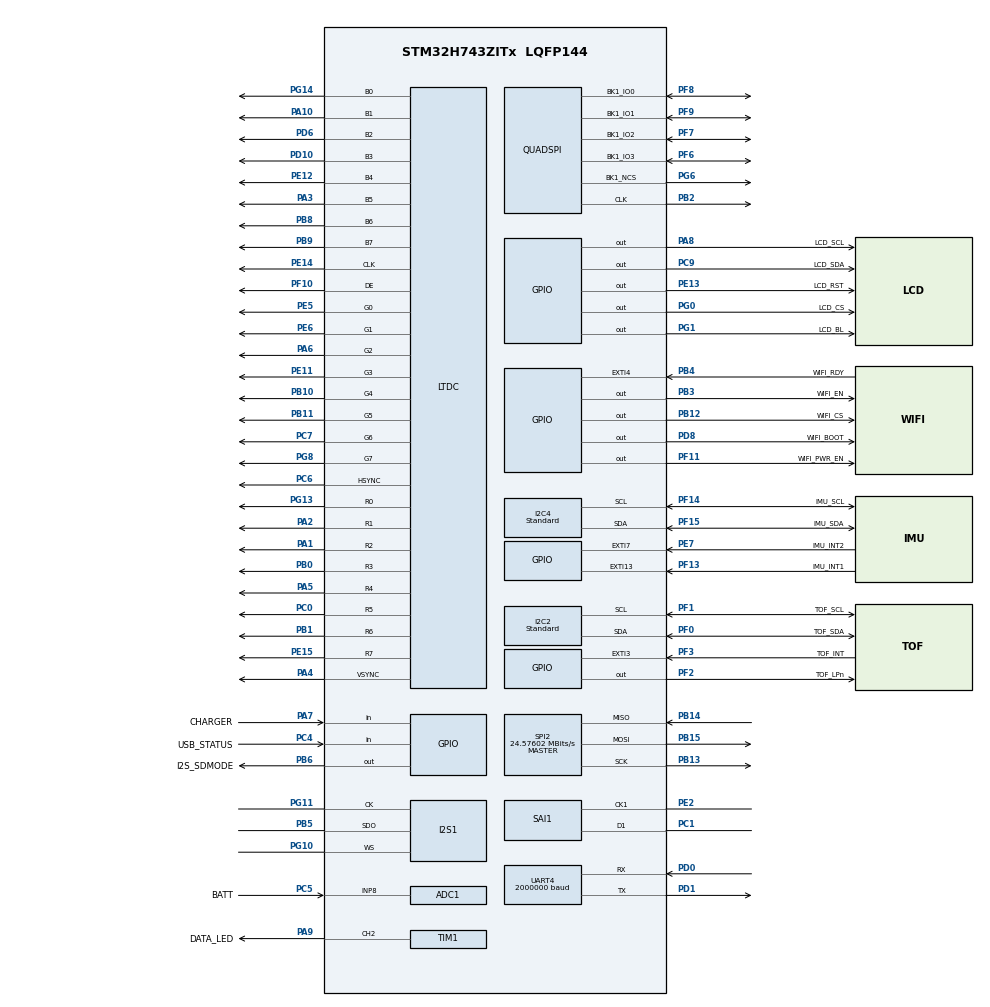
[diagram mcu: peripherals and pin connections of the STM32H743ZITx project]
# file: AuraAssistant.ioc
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ADC1.Channel-0\#ChannelRegularConversion=ADC_CHANNEL_8
ADC1.ClockPrescaler=ADC_CLOCK_ASYNC_DIV4
ADC1.EnableInjectedConversion=DISABLE
ADC1.NbrOfConversion=1
ADC1.NbrOfConversionFlag=1
ADC1.OffsetNumber-0\#ChannelRegularConversion=ADC_OFFSET_NONE
ADC1.OffsetSignedSaturation-0\#ChannelRegularConversion=DISABLE
ADC1.OversamplingMode=ENABLE
ADC1.Rank-0\#ChannelRegularConversion=1
ADC1.Ratio=16
ADC1.Resolution=ADC_RESOLUTION_16B
ADC1.RightBitShift=ADC_RIGHTBITSHIFT_4
ADC1.SamplingTime-0\#ChannelRegularConversion=ADC_SAMPLETIME_387CYCLES_5
ADC1.master=1
CORTEX_M7.AccessPermission_S-Cortex_Memory_Protection_Unit_Region1_Settings_S=MPU_REGION_PRIV_RO_URO
CORTEX_M7.AccessPermission_S-Cortex_Memory_Protection_Unit_Region2_Settings_S=MPU_REGION_FULL_ACCESS
CORTEX_M7.BaseAddress_S-Cortex_Memory_Protection_Unit_Region1_Settings_S=0x90000000
CORTEX_M7.BaseAddress_S-Cortex_Memory_Protection_Unit_Region2_Settings_S=0x24000000
CORTEX_M7.CPU_DCache=Enabled
CORTEX_M7.CPU_ICache=Enabled
CORTEX_M7.DisableExec_S-Cortex_Memory_Protection_Unit_Region1_Settings_S=MPU_INSTRUCTION_ACCESS_DISABLE
CORTEX_M7.DisableExec_S-Cortex_Memory_Protection_Unit_Region2_Settings_S=MPU_INSTRUCTION_ACCESS_DISABLE
CORTEX_M7.Enable_S-Cortex_Memory_Protection_Unit_Region1_Settings_S=MPU_REGION_ENABLE
CORTEX_M7.Enable_S-Cortex_Memory_Protection_Unit_Region2_Settings_S=MPU_REGION_ENABLE
CORTEX_M7.IsCacheable_S-Cortex_Memory_Protection_Unit_Region1_Settings_S=MPU_ACCESS_CACHEABLE
CORTEX_M7.IsCacheable_S-Cortex_Memory_Protection_Unit_Region2_Settings_S=MPU_ACCESS_NOT_CACHEABLE
CORTEX_M7.Size_S-Cortex_Memory_Protection_Unit_Region1_Settings_S=MPU_REGION_SIZE_16MB
CORTEX_M7.Size_S-Cortex_Memory_Protection_Unit_Region2_Settings_S=MPU_REGION_SIZE_512KB
CORTEX_M7.SubRegionDisable_S-Cortex_Memory_Protection_Unit_Region1_Settings_S=0x00
CORTEX_M7.SubRegionDisable_S-Cortex_Memory_Protection_Unit_Region2_Settings_S=0x00
CORTEX_M7.TypeExtField_S-Cortex_Memory_Protection_Unit_Region2_Settings_S=MPU_TEX_LEVEL1
CORTEX_M7.default_mode_Activation=1
DMA2D.ColorMode=DMA2D_OUTPUT_RGB565
Dma.Request0=SPI1_TX
Dma.Request1=SAI1_A
Dma.Request2=TIM1_CH2
Dma.Request3=SPI2_TX
Dma.Request4=SPI2_RX
Dma.SAI1_A.1.Direction=DMA_PERIPH_TO_MEMORY
Dma.SAI1_A.1.EventEnable=DISABLE
Dma.SAI1_A.1.FIFOMode=DMA_FIFOMODE_DISABLE
Dma.SAI1_A.1.Instance=DMA1_Stream1
Dma.SAI1_A.1.MemDataAlignment=DMA_MDATAALIGN_HALFWORD
Dma.SAI1_A.1.MemInc=DMA_MINC_ENABLE
Dma.SAI1_A.1.Mode=DMA_CIRCULAR
Dma.SAI1_A.1.PeriphDataAlignment=DMA_PDATAALIGN_HALFWORD
Dma.SAI1_A.1.PeriphInc=DMA_PINC_DISABLE
Dma.SAI1_A.1.Polarity=HAL_DMAMUX_REQ_GEN_RISING
Dma.SAI1_A.1.Priority=DMA_PRIORITY_HIGH
Dma.SAI1_A.1.RequestNumber=1
Dma.SAI1_A.1.SignalID=NONE
Dma.SAI1_A.1.SyncEnable=DISABLE
Dma.SAI1_A.1.SyncPolarity=HAL_DMAMUX_SYNC_NO_EVENT
Dma.SAI1_A.1.SyncRequestNumber=1
Dma.SAI1_A.1.SyncSignalID=NONE
Dma.SPI1_TX.0.Direction=DMA_MEMORY_TO_PERIPH
Dma.SPI1_TX.0.EventEnable=DISABLE
Dma.SPI1_TX.0.FIFOMode=DMA_FIFOMODE_DISABLE
Dma.SPI1_TX.0.Instance=DMA1_Stream0
Dma.SPI1_TX.0.MemDataAlignment=DMA_MDATAALIGN_HALFWORD
Dma.SPI1_TX.0.MemInc=DMA_MINC_ENABLE
Dma.SPI1_TX.0.Mode=DMA_NORMAL
Dma.SPI1_TX.0.PeriphDataAlignment=DMA_PDATAALIGN_HALFWORD
Dma.SPI1_TX.0.PeriphInc=DMA_PINC_DISABLE
Dma.SPI1_TX.0.Polarity=HAL_DMAMUX_REQ_GEN_RISING
Dma.SPI1_TX.0.Priority=DMA_PRIORITY_HIGH
Dma.SPI1_TX.0.RequestNumber=1
Dma.SPI1_TX.0.SignalID=NONE
Dma.SPI1_TX.0.SyncEnable=DISABLE
Dma.SPI1_TX.0.SyncPolarity=HAL_DMAMUX_SYNC_NO_EVENT
Dma.SPI1_TX.0.SyncRequestNumber=1
Dma.SPI1_TX.0.SyncSignalID=NONE
Dma.SPI2_RX.4.Direction=DMA_PERIPH_TO_MEMORY
Dma.SPI2_RX.4.EventEnable=DISABLE
Dma.SPI2_RX.4.FIFOMode=DMA_FIFOMODE_DISABLE
Dma.SPI2_RX.4.Instance=DMA1_Stream2
Dma.SPI2_RX.4.MemDataAlignment=DMA_MDATAALIGN_BYTE
Dma.SPI2_RX.4.MemInc=DMA_MINC_ENABLE
Dma.SPI2_RX.4.Mode=DMA_NORMAL
Dma.SPI2_RX.4.PeriphDataAlignment=DMA_PDATAALIGN_BYTE
Dma.SPI2_RX.4.PeriphInc=DMA_PINC_DISABLE
Dma.SPI2_RX.4.Polarity=HAL_DMAMUX_REQ_GEN_RISING
Dma.SPI2_RX.4.Priority=DMA_PRIORITY_HIGH
Dma.SPI2_RX.4.RequestNumber=1
Dma.SPI2_RX.4.SignalID=NONE
Dma.SPI2_RX.4.SyncEnable=DISABLE
Dma.SPI2_RX.4.SyncPolarity=HAL_DMAMUX_SYNC_NO_EVENT
Dma.SPI2_RX.4.SyncRequestNumber=1
Dma.SPI2_RX.4.SyncSignalID=NONE
Dma.SPI2_TX.3.Direction=DMA_MEMORY_TO_PERIPH
Dma.SPI2_TX.3.EventEnable=DISABLE
Dma.SPI2_TX.3.FIFOMode=DMA_FIFOMODE_DISABLE
Dma.SPI2_TX.3.Instance=DMA1_Stream3
Dma.SPI2_TX.3.MemDataAlignment=DMA_MDATAALIGN_BYTE
Dma.SPI2_TX.3.MemInc=DMA_MINC_ENABLE
Dma.SPI2_TX.3.Mode=DMA_NORMAL
Dma.SPI2_TX.3.PeriphDataAlignment=DMA_PDATAALIGN_BYTE
Dma.SPI2_TX.3.PeriphInc=DMA_PINC_DISABLE
Dma.SPI2_TX.3.Polarity=HAL_DMAMUX_REQ_GEN_RISING
Dma.SPI2_TX.3.Priority=DMA_PRIORITY_HIGH
Dma.SPI2_TX.3.RequestNumber=1
Dma.SPI2_TX.3.SignalID=NONE
Dma.SPI2_TX.3.SyncEnable=DISABLE
Dma.SPI2_TX.3.SyncPolarity=HAL_DMAMUX_SYNC_NO_EVENT
Dma.SPI2_TX.3.SyncRequestNumber=1
Dma.SPI2_TX.3.SyncSignalID=NONE
Dma.TIM1_CH2.2.Direction=DMA_MEMORY_TO_PERIPH
Dma.TIM1_CH2.2.EventEnable=DISABLE
Dma.TIM1_CH2.2.FIFOMode=DMA_FIFOMODE_DISABLE
Dma.TIM1_CH2.2.Instance=DMA1_Stream4
Dma.TIM1_CH2.2.MemDataAlignment=DMA_MDATAALIGN_HALFWORD
Dma.TIM1_CH2.2.MemInc=DMA_MINC_ENABLE
Dma.TIM1_CH2.2.Mode=DMA_NORMAL
Dma.TIM1_CH2.2.PeriphDataAlignment=DMA_PDATAALIGN_HALFWORD
Dma.TIM1_CH2.2.PeriphInc=DMA_PINC_DISABLE
Dma.TIM1_CH2.2.Polarity=HAL_DMAMUX_REQ_GEN_RISING
Dma.TIM1_CH2.2.Priority=DMA_PRIORITY_MEDIUM
Dma.TIM1_CH2.2.RequestNumber=1
Dma.TIM1_CH2.2.SignalID=NONE
Dma.TIM1_CH2.2.SyncEnable=DISABLE
Dma.TIM1_CH2.2.SyncPolarity=HAL_DMAMUX_SYNC_NO_EVENT
Dma.TIM1_CH2.2.SyncRequestNumber=1
Dma.TIM1_CH2.2.SyncSignalID=NONE
FREERTOS.BinarySemaphores01=WiFiReadySem,Dynamic,NULL,Depleted
FREERTOS.Tasks01=SystemTask,24,1024,System_Task,Default,NULL,Dynamic,NULL,NULL;TouchGFXTask,24,4096,TouchGFX_Task,As external,NULL,Dynamic,NULL,NULL;AudioInputTask,40,2048,AudioInput_Task,Default,NULL,Dynamic,NULL,NULL;WiFiTask,32,2048,WiFi_Task,Default,NULL,Dynamic,NULL,NULL;SensorTask,24,1024,Sensor_Task,Default,NULL,Dynamic,NULL,NULL;PowerTask,8,512,Power_Task,Default,NULL,Dynamic,NULL,NULL;LEDTask,16,512,LED_Task,Default,NULL,Dynamic,NULL,NULL;LoggingTask,8,1024,Logging_Task,Default,NULL,Dynamic,NULL,NULL;AudioOutputTask,40,2048,AudioOutput_Task,Default,NULL,Dynamic,NULL,NULL
FREERTOS.configCHECK_FOR_STACK_OVERFLOW=1
FREERTOS.configTOTAL_HEAP_SIZE=96000
FREERTOS.configUSE_NEWLIB_REENTRANT=1
I2C2.I2C_Speed_Mode=I2C_Standard
I2C2.Timing=0x307075B1
I2C4.I2C_Speed_Mode=I2C_Standard
I2C4.Timing=0x307075B1
I2S1.AudioFreq=I2S_AUDIOFREQ_48K
I2S1.ErrorAudioFreq=0.0 %
I2S1.Instance=SPI$Index
I2S1.RealAudioFreq=48.0 KHz
LTDC.ActiveW=480
LTDC.Alpha_L0=255
LTDC.HBP=20
LTDC.HFP=20
LTDC.ImageHeight_L0=480
LTDC.ImageWidth_L0=480
LTDC.Layers=0
LTDC.PixelFormat_L0=LTDC_PIXEL_FORMAT_RGB565
LTDC.PCPolarity=LTDC_PCPOLARITY_IIPC
LTDC.VBP=16
LTDC.VFP=16
LTDC.WindowX1_L0=480
LTDC.WindowY1_L0=480
Mcu.Family=STM32H7
Mcu.Name=STM32H743ZITx
Mcu.Package=LQFP144
NVIC.DMA1_Stream0_IRQn=true\:5\:0\:false\:false\:true\:true\:false\:true\:true
NVIC.DMA1_Stream1_IRQn=true\:5\:0\:false\:false\:true\:true\:false\:true\:true
NVIC.DMA1_Stream2_IRQn=true\:6\:0\:true\:false\:true\:true\:false\:true\:true
NVIC.DMA1_Stream3_IRQn=true\:6\:0\:true\:false\:true\:true\:false\:true\:true
NVIC.DMA1_Stream4_IRQn=true\:7\:0\:true\:false\:true\:true\:false\:true\:true
NVIC.DMA2D_IRQn=true\:6\:0\:true\:false\:true\:true\:true\:true\:true
NVIC.EXTI15_10_IRQn=true\:8\:0\:true\:false\:true\:true\:true\:true\:true
NVIC.EXTI3_IRQn=true\:7\:0\:true\:false\:true\:true\:true\:true\:true
NVIC.EXTI4_IRQn=true\:6\:0\:true\:false\:true\:true\:true\:true\:true
NVIC.EXTI9_5_IRQn=true\:8\:0\:true\:false\:true\:true\:true\:true\:true
NVIC.LTDC_IRQn=true\:5\:0\:true\:false\:true\:true\:true\:true\:true
NVIC.PriorityGroup=NVIC_PRIORITYGROUP_4
NVIC.SAI1_IRQn=true\:6\:0\:true\:false\:true\:true\:true\:true\:true
NVIC.SPI1_IRQn=true\:5\:0\:false\:false\:true\:true\:true\:true\:true
NVIC.SPI2_IRQn=true\:6\:0\:true\:false\:true\:true\:false\:true\:true
NVIC.TIM6_DAC_IRQn=true\:4\:0\:true\:false\:true\:false\:false\:true\:true
NVIC.TimeBase=TIM6_DAC_IRQn
NVIC.TimeBaseIP=TIM6
PA1.GPIO_Speed=GPIO_SPEED_FREQ_MEDIUM
PA1.Mode=RGB888
PA1.Signal=LTDC_R2
PA10.GPIO_Speed=GPIO_SPEED_FREQ_MEDIUM
PA10.Mode=RGB888
PA10.Signal=LTDC_B1
PA13\ (JTMS/SWDIO).Mode=Serial_Wire
PA13\ (JTMS/SWDIO).Signal=DEBUG_JTMS-SWDIO
PA14\ (JTCK/SWCLK).Mode=Serial_Wire
PA14\ (JTCK/SWCLK).Signal=DEBUG_JTCK-SWCLK
PA2.GPIO_Speed=GPIO_SPEED_FREQ_MEDIUM
PA2.Mode=RGB888
PA2.Signal=LTDC_R1
PA3.GPIO_Speed=GPIO_SPEED_FREQ_MEDIUM
PA3.Mode=RGB888
PA3.Signal=LTDC_B5
PA4.GPIO_Speed=GPIO_SPEED_FREQ_MEDIUM
PA4.Mode=RGB888
PA4.Signal=LTDC_VSYNC
PA5.GPIO_Speed=GPIO_SPEED_FREQ_MEDIUM
PA5.Mode=RGB888
PA5.Signal=LTDC_R4
PA6.GPIO_Speed=GPIO_SPEED_FREQ_MEDIUM
PA6.Mode=RGB888
PA6.Signal=LTDC_G2
PA7.GPIO_Label=CHARGER
PA7.Signal=GPIO_Input
PA8.GPIO_Label=LCD_SCL
PA8.Signal=GPIO_Output
PA9.GPIO_Label=DATA_LED
PA9.GPIO_Speed=GPIO_SPEED_FREQ_VERY_HIGH
PA9.Signal=S_TIM1_CH2
PB0.GPIO_Speed=GPIO_SPEED_FREQ_MEDIUM
PB0.Mode=RGB888
PB0.Signal=LTDC_R3
PB1.GPIO_Speed=GPIO_SPEED_FREQ_MEDIUM
PB1.Mode=RGB888
PB1.Signal=LTDC_R6
PB10.GPIO_Speed=GPIO_SPEED_FREQ_MEDIUM
PB10.Mode=RGB888
PB10.Signal=LTDC_G4
PB11.GPIO_Speed=GPIO_SPEED_FREQ_MEDIUM
PB11.Mode=RGB888
PB11.Signal=LTDC_G5
PB12.GPIO_Label=WIFI_CS
PB12.GPIO_Speed=GPIO_SPEED_FREQ_VERY_HIGH
PB12.Signal=GPIO_Output
PB13.GPIO_Speed=GPIO_SPEED_FREQ_VERY_HIGH
PB13.Mode=Full_Duplex_Master
PB13.Signal=SPI2_SCK
PB14.GPIO_Speed=GPIO_SPEED_FREQ_VERY_HIGH
PB14.Mode=Full_Duplex_Master
PB14.Signal=SPI2_MISO
PB15.GPIO_Speed=GPIO_SPEED_FREQ_VERY_HIGH
PB15.Mode=Full_Duplex_Master
PB15.Signal=SPI2_MOSI
PB2.GPIO_Speed=GPIO_SPEED_FREQ_VERY_HIGH
PB2.Mode=Single Bank 1
PB2.Signal=QUADSPI_CLK
PB3\ (JTDO/TRACESWO).GPIO_Label=WIFI_EN
PB3\ (JTDO/TRACESWO).PinAttribute=Free
PB3\ (JTDO/TRACESWO).Signal=GPIO_Output
PB4\ (NJTRST).GPIO_Label=WIFI_RDY
PB4\ (NJTRST).GPIO_ModeDefaultEXTI=GPIO_MODE_IT_RISING_FALLING
PB4\ (NJTRST).Signal=GPXTI4
PB5.Mode=Half_Duplex_Master_Tx
PB5.PinAttribute=Free
PB5.Signal=I2S1_SDO
PB6.GPIO_Label=I2S_SDMODE
PB6.PinAttribute=Free
PB6.PinState=GPIO_PIN_RESET
PB6.Signal=GPIO_Output
PB8.GPIO_Speed=GPIO_SPEED_FREQ_MEDIUM
PB8.Mode=RGB888
PB8.PinAttribute=Free
PB8.Signal=LTDC_B6
PB9.GPIO_Speed=GPIO_SPEED_FREQ_MEDIUM
PB9.Mode=RGB888
PB9.PinAttribute=Free
PB9.Signal=LTDC_B7
PC0.GPIO_Speed=GPIO_SPEED_FREQ_MEDIUM
PC0.Mode=RGB888
PC0.Signal=LTDC_R5
PC1.Mode=PDM_Master_Mode_CK1
PC1.Signal=SAI1_D1
PC14-OSC32_IN\ (OSC32_IN).Mode=LSE-External-Oscillator
PC14-OSC32_IN\ (OSC32_IN).Signal=RCC_OSC32_IN
PC15-OSC32_OUT\ (OSC32_OUT).Mode=LSE-External-Oscillator
PC15-OSC32_OUT\ (OSC32_OUT).Signal=RCC_OSC32_OUT
PC4.GPIO_Label=USB_STATUS
PC4.Signal=GPIO_Input
PC5.GPIO_Label=BATT
PC5.Signal=ADCx_INP8
PC6.GPIO_Speed=GPIO_SPEED_FREQ_MEDIUM
PC6.Mode=RGB888
PC6.Signal=LTDC_HSYNC
PC7.GPIO_Speed=GPIO_SPEED_FREQ_MEDIUM
PC7.Mode=RGB888
PC7.Signal=LTDC_G6
PC9.GPIO_Label=LCD_SDA
PC9.Signal=GPIO_Output
PD0.GPIO_Speed=GPIO_SPEED_FREQ_HIGH
PD0.Mode=Asynchronous
PD0.Signal=UART4_RX
PD1.GPIO_Speed=GPIO_SPEED_FREQ_HIGH
PD1.Mode=Asynchronous
PD1.Signal=UART4_TX
PD10.GPIO_Speed=GPIO_SPEED_FREQ_MEDIUM
PD10.Mode=RGB888
PD10.Signal=LTDC_B3
PD6.GPIO_Speed=GPIO_SPEED_FREQ_MEDIUM
PD6.Mode=RGB888
PD6.Signal=LTDC_B2
PD8.GPIO_Label=WIFI_BOOT
PD8.Signal=GPIO_Output
PE11.GPIO_Speed=GPIO_SPEED_FREQ_MEDIUM
PE11.Mode=RGB888
PE11.Signal=LTDC_G3
PE12.GPIO_Speed=GPIO_SPEED_FREQ_MEDIUM
PE12.Mode=RGB888
PE12.Signal=LTDC_B4
PE13.GPIO_Label=LCD_RST
PE13.Signal=GPIO_Output
PE14.GPIO_Speed=GPIO_SPEED_FREQ_MEDIUM
PE14.Mode=RGB888
PE14.Signal=LTDC_CLK
PE15.GPIO_Speed=GPIO_SPEED_FREQ_MEDIUM
PE15.Mode=RGB888
PE15.Signal=LTDC_R7
PE2.Mode=PDM_Master_Mode_CK1
PE2.Signal=SAI1_CK1
PE5.GPIO_Speed=GPIO_SPEED_FREQ_MEDIUM
PE5.Mode=RGB888
PE5.Signal=LTDC_G0
PE6.GPIO_Speed=GPIO_SPEED_FREQ_MEDIUM
PE6.Mode=RGB888
PE6.Signal=LTDC_G1
PE7.GPIO_Label=IMU_INT2
PE7.GPIO_ModeDefaultEXTI=GPIO_MODE_IT_RISING
PE7.Signal=GPXTI7
PF0.GPIO_Label=TOF_SDA
PF0.GPIO_Pu=GPIO_PULLUP
PF0.Mode=I2C
PF0.Signal=I2C2_SDA
PF1.GPIO_Label=TOF_SCL
PF1.GPIO_Pu=GPIO_PULLUP
PF1.Mode=I2C
PF1.Signal=I2C2_SCL
PF10.GPIO_Speed=GPIO_SPEED_FREQ_MEDIUM
PF10.Mode=RGB888
PF10.Signal=LTDC_DE
PF11.GPIO_Label=WIFI_PWR_EN
PF11.Signal=GPIO_Output
PF13.GPIO_Label=IMU_INT1
PF13.GPIO_ModeDefaultEXTI=GPIO_MODE_IT_RISING
PF13.Signal=GPXTI13
PF14.GPIO_Label=IMU_SCL
PF14.GPIO_Pu=GPIO_PULLUP
PF14.Mode=I2C
PF14.Signal=I2C4_SCL
PF15.GPIO_Label=IMU_SDA
PF15.GPIO_Pu=GPIO_PULLUP
PF15.Mode=I2C
PF15.Signal=I2C4_SDA
PF2.GPIO_Label=TOF_LPn
PF2.PinState=GPIO_PIN_SET
PF2.Signal=GPIO_Output
PF3.GPIO_Label=TOF_INT
PF3.GPIO_ModeDefaultEXTI=GPIO_MODE_IT_FALLING
PF3.Signal=GPXTI3
PF6.GPIO_Speed=GPIO_SPEED_FREQ_VERY_HIGH
PF6.Mode=Single Bank 1
PF6.Signal=QUADSPI_BK1_IO3
PF7.GPIO_Speed=GPIO_SPEED_FREQ_VERY_HIGH
PF7.Mode=Single Bank 1
PF7.Signal=QUADSPI_BK1_IO2
PF8.GPIO_Speed=GPIO_SPEED_FREQ_VERY_HIGH
PF8.Mode=Single Bank 1
PF8.Signal=QUADSPI_BK1_IO0
PF9.GPIO_Speed=GPIO_SPEED_FREQ_VERY_HIGH
PF9.Mode=Single Bank 1
PF9.Signal=QUADSPI_BK1_IO1
PG0.GPIO_Label=LCD_CS
PG0.PinState=GPIO_PIN_SET
PG0.Signal=GPIO_Output
PG1.GPIO_Label=LCD_BL
PG1.PinState=GPIO_PIN_RESET
PG1.Signal=GPIO_Output
PG10.Mode=Half_Duplex_Master_Tx
PG10.Signal=I2S1_WS
PG11.Mode=Half_Duplex_Master_Tx
PG11.PinAttribute=Free
PG11.Signal=I2S1_CK
PG13.GPIO_Speed=GPIO_SPEED_FREQ_MEDIUM
PG13.Mode=RGB888
PG13.PinAttribute=Free
PG13.Signal=LTDC_R0
PG14.GPIO_Speed=GPIO_SPEED_FREQ_MEDIUM
PG14.Mode=RGB888
PG14.PinAttribute=Free
PG14.Signal=LTDC_B0
PG6.GPIO_Speed=GPIO_SPEED_FREQ_VERY_HIGH
PG6.Mode=Single Bank 1
PG6.Signal=QUADSPI_BK1_NCS
PG8.GPIO_Speed=GPIO_SPEED_FREQ_MEDIUM
PG8.Mode=RGB888
PG8.Signal=LTDC_G7
PH0-OSC_IN\ (PH0).Mode=HSE-External-Oscillator
PH0-OSC_IN\ (PH0).Signal=RCC_OSC_IN
PH1-OSC_OUT\ (PH1).Mode=HSE-External-Oscillator
PH1-OSC_OUT\ (PH1).Signal=RCC_OSC_OUT
ProjectManager.HeapSize=0x200
ProjectManager.StackSize=0x400
ProjectManager.TargetToolchain=CMake
QUADSPI.ChipSelectHighTime=QSPI_CS_HIGH_TIME_7_CYCLE
QUADSPI.ClockPrescaler=1
QUADSPI.FifoThreshold=4
QUADSPI.FlashSize=23
QUADSPI.SampleShifting=QSPI_SAMPLE_SHIFTING_HALFCYCLE
RCC.ADCFreq_Value=49152038.57421875
RCC.APB1Freq_Value=120000000
RCC.APB2Freq_Value=120000000
RCC.APB3Freq_Value=120000000
RCC.APB4Freq_Value=120000000
RCC.CortexFreq_Value=480000000
RCC.D1PPRE=RCC_APB3_DIV2
RCC.D2PPRE1=RCC_APB1_DIV2
RCC.D2PPRE2=RCC_APB2_DIV2
RCC.D3PPRE=RCC_APB4_DIV2
RCC.DIVM1=5
RCC.DIVM2=5
RCC.DIVM3=2
RCC.DIVN1=192
RCC.DIVN2=98
RCC.DIVN3=32
RCC.DIVP2=10
RCC.DIVP3=1
RCC.DIVQ1=8
RCC.DIVQ2=4
RCC.DIVR3=25
RCC.EnbaleCSS=true
RCC.HCLKFreq_Value=240000000
RCC.HPRE=RCC_HCLK_DIV2
RCC.PLL2FRACN=2491
RCC.PLL3FRACN=0
RCC.PLLFRACN=0
RCC.PLLSourceVirtual=RCC_PLLSOURCE_HSE
RCC.SAI1CLockSelection=RCC_SAI1CLKSOURCE_PLL2
RCC.SPI123CLockSelection=RCC_SPI123CLKSOURCE_PLL2
RCC.SYSCLKFreq_VALUE=480000000
RCC.SYSCLKSource=RCC_SYSCLKSOURCE_PLLCLK
RCC.USBFreq_Value=120000000
SAI1.Activation=ENABLE
SAI1.AudioFrequency-PDM_Master_Mode_CK1=SAI_AUDIO_FREQUENCY_MCKDIV
SAI1.DataSize-PDM_Master_Mode_CK1=SAI_DATASIZE_16
SAI1.ErrorAudioFreq-PDM_Master_Mode_CK1=1100.0 %
SAI1.FSPolarity-PDM_Master_Mode_CK1=SAI_FS_ACTIVE_HIGH
SAI1.FrameLength-PDM_Master_Mode_CK1=16
SAI1.Instance-PDM_Master_Mode_CK1=SAI$Index_Block_A
SAI1.MClockEnable-PDM_Master_Mode_CK1=SAI_MASTERCLOCK_DISABLE
SAI1.MckOverSampling-PDM_Master_Mode_CK1=SAI_MCK_OVERSAMPLING_DISABLE
SAI1.Mckdiv-PDM_Master_Mode_CK1=12
SAI1.MicPairsNbr=1
SAI1.NoDivider-PDM_Master_Mode_CK1=SAI_MASTERDIVIDER_DISABLE
SAI1.RealAudioFreq-PDM_Master_Mode_CK1=0 Hz
SAI1.SlotActive-PDM_Master_Mode_CK1=0x0000FFFF
SAI1.SlotNumber-PDM_Master_Mode_CK1=1
SAI1.VirtualMode-PDM_Master_Mode_CK1=VM_MASTER
SAI1.VirtualProtocol-PDM_Master_Mode_CK1=VM_PDM_PROTOCOL
SAI1.VirtualSlotActive-PDM_Master_Mode_CK1=SAI_SLOTACTIVE_ALL
SH.ADCx_INP8.0=ADC1_INP8,IN8-Single-Ended
SH.S_TIM1_CH2.0=TIM1_CH2,PWM Generation2 CH2
SPI2.BaudRatePrescaler=SPI_BAUDRATEPRESCALER_2
SPI2.CalculateBaudRate=24.57602 MBits/s
SPI2.DataSize=SPI_DATASIZE_8BIT
SPI2.Direction=SPI_DIRECTION_2LINES
SPI2.Mode=SPI_MODE_MASTER
SPI2.NSSPMode=SPI_NSS_PULSE_DISABLE
SPI2.TIMode=SPI_TIMODE_DISABLE
SPI2.VirtualType=VM_MASTER
STMicroelectronics.X-CUBE-ST67W61.1.3.0.BSP.number=1
STMicroelectronics.X-CUBE-ST67W61.1.3.0.ST67W6XIiNetworkIiDriverCcNetworkJjATDriver=true
STMicroelectronics.X-CUBE-ST67W61.1.3.0.ST67W6XIiNetworkIiDriverCcNetworkJjST67OoArchitecture=T01
STMicroelectronics.X-CUBE-ST67W61.1.3.0.ST67W6XIiNetworkIiDriverCcNetworkJjServiceAPI=true
STMicroelectronics.X-CUBE-ST67W61.1.3.0.USE_BLE=1
STMicroelectronics.X-CUBE-ST67W61.1.3.0.USE_NET=1
STMicroelectronics.X-CUBE-ST67W61.1.3.0.USE_WIFI_STA=1
STMicroelectronics.X-CUBE-ST67W61.1.3.0.W6X_BLE_HOSTNAME=AuraAssistant
STMicroelectronics.X-CUBE-ST67W61.1.3.0.W6X_CLOCK_MODE=2
STMicroelectronics.X-CUBE-ST67W61.1.3.0.W6X_NET_DHCP_MODE=1
STMicroelectronics.X-CUBE-ST67W61.1.3.0.W6X_NET_HOSTNAME=AuraAssistant
STMicroelectronics.X-CUBE-ST67W61.1.3.0.W6X_POWER_SAVE_AUTO=0
STMicroelectronics.X-CUBE-ST67W61.1.3.00.BSP.STBoard=false
STMicroelectronics.X-CUBE-ST67W61.1.3.00.BSP.api=Unknown
STMicroelectronics.X-CUBE-ST67W61.1.3.00.BSP.instance=SPI2
STMicroelectronics.X-CUBE-ST67W61.1.3.00.BSP.ip=SPI
STMicroelectronics.X-CUBE-ST67W61.1.3.00.BSP.mode=Full-Duplex Master
STMicroelectronics.X-CUBE-ST67W61.1.3.00.BSP.name=NCP_SPI
STMicroelectronics.X-CUBE-ST67W61.1.3.00.BSP.solution=SPI2
STMicroelectronics.X-CUBE-TOUCHGFX.4.26.1.ApplicationCcGraphicsJjApplication=TouchGFXOoGenerator
STMicroelectronics.X-CUBE-TOUCHGFX.4.26.1.tgfx_custom_height=480
STMicroelectronics.X-CUBE-TOUCHGFX.4.26.1.tgfx_display_interface=disp_ltdc
STMicroelectronics.X-CUBE-TOUCHGFX.4.26.1.tgfx_hardware_accelerator=dma_2d
STMicroelectronics.X-CUBE-TOUCHGFX.4.26.1.tgfx_oswrapper=CMSIS V2
STMicroelectronics.X-CUBE-TOUCHGFX.4.26.1.tgfx_vsync=vsync_ltdc
STMicroelectronics.X-CUBE-TOUCHGFX.4.26.1_IsPackSelfContextualization=true
TIM1.Channel-PWM\ Generation2\ CH2=TIM_CHANNEL_2
TIM1.Period=299
UART4.BaudRate=2000000
VP_CRC_VS_CRC.Mode=CRC_Activate
VP_DMA2D_VS_DMA2D.Mode=DMA2D_Activate
VP_FREERTOS_VS_CMSIS_V2.Mode=CMSIS_V2
VP_MEMORYMAP_VS_MEMORYMAP.Mode=CurAppReg
VP_STMicroelectronics.X-CUBE-ST67W61_VS_NetworkJjST67W6XIiNetworkIiDriver_1.3.0_1.3.0.Mode=NetworkJjST67W6XIiNetworkIiDriver
VP_STMicroelectronics.X-CUBE-TOUCHGFX_VS_GraphicsJjApplication_4.26.1.Mode=GraphicsJjApplication
VP_SYS_VS_tim6.Mode=TIM6
VP_TIM1_VS_ClockSourceINT.Mode=Internal
board=custom

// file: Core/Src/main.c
/* USER CODE BEGIN Header */
/**
  ******************************************************************************
  * @file           : main.c
  * @brief          : Main program body
  ******************************************************************************
  * @attention
  *
  * Copyright (c) 2026 STMicroelectronics.
  * All rights reserved.
  *
  * This software is licensed under terms that can be found in the LICENSE file
  * in the root directory of this software component.
  * If no LICENSE file comes with this software, it is provided AS-IS.
  *
  ******************************************************************************
  */
/* USER CODE END Header */
#include "main.h"
#include "FreeRTOS.h"
#include "cmsis_os2.h"
#include "adc.h"
#include "crc.h"
#include "dma.h"
#include "dma2d.h"
#include "i2c.h"
#include "i2s.h"
#include "ltdc.h"
#include "quadspi.h"
#include "sai.h"
#include "spi.h"
#include "tim.h"
#include "usart.h"
#include "gpio.h"
#include "app_touchgfx.h"

/* USER CODE BEGIN Includes */
#include "app.h"
#include "bsp_audio_in.h"
#include "bsp_audio_out.h"
#include "bsp_led.h"
#include "bsp_lcd.h"
/* USER CODE END Includes */

void SystemClock_Config(void);
void PeriphCommonClock_Config(void);
static void MPU_Config(void);
void MX_FREERTOS_Init(void);

int main(void)
{

  /* MPU Configuration--------------------------------------------------------*/
  MPU_Config();

  /* Enable caches only after the MPU has marked the LTDC framebuffer as
     non-cacheable and the memory-mapped QSPI aperture as read-only/cacheable. */
  SCB_EnableICache();
  SCB_EnableDCache();

  /* MCU Configuration--------------------------------------------------------*/

  /* Reset of all peripherals, Initializes the Flash interface and the Systick. */
  HAL_Init();

  /* Configure the system clock */
  SystemClock_Config();

  /* Configure the peripherals common clocks */
  PeriphCommonClock_Config();

  /* Initialize all configured peripherals */
  MX_GPIO_Init();
  MX_DMA_Init();
  MX_LTDC_Init();
  MX_I2C4_Init();
  MX_I2S1_Init();
  MX_SAI1_Init();
  MX_SPI2_Init();
  MX_TIM1_Init();
  MX_UART4_Init();
  MX_QUADSPI_Init();
  MX_I2C2_Init();
  MX_DMA2D_Init();
  MX_CRC_Init();
  MX_ADC1_Init();
  MX_TouchGFX_Init();
  /* Call PreOsInit function */

  /* Init scheduler */
  osKernelInitialize();  /* Call init function for freertos objects (in cmsis_os2.c) */
  MX_FREERTOS_Init();

  /* Start scheduler */
  osKernelStart();

  /* We should never get here as control is now taken by the scheduler */

  /* Infinite loop */
  while (1)
  {

  }
}

void SystemClock_Config(void)
{
  RCC_OscInitTypeDef RCC_OscInitStruct = {0};
  RCC_ClkInitTypeDef RCC_ClkInitStruct = {0};

  /** Supply configuration update enable
  */
  HAL_PWREx_ConfigSupply(PWR_LDO_SUPPLY);

  /** Configure the main internal regulator output voltage
  */
  __HAL_PWR_VOLTAGESCALING_CONFIG(PWR_REGULATOR_VOLTAGE_SCALE0);

  while(!__HAL_PWR_GET_FLAG(PWR_FLAG_VOSRDY)) {}

  /** Initializes the RCC Oscillators according to the specified parameters
  * in the RCC_OscInitTypeDef structure.
  */
  RCC_OscInitStruct.OscillatorType = RCC_OSCILLATORTYPE_HSE;
  RCC_OscInitStruct.HSEState = RCC_HSE_ON;
  RCC_OscInitStruct.PLL.PLLState = RCC_PLL_ON;
  RCC_OscInitStruct.PLL.PLLSource = RCC_PLLSOURCE_HSE;
  RCC_OscInitStruct.PLL.PLLM = 5;
  RCC_OscInitStruct.PLL.PLLN = 192;
  RCC_OscInitStruct.PLL.PLLP = 2;
  RCC_OscInitStruct.PLL.PLLQ = 8;
  RCC_OscInitStruct.PLL.PLLR = 2;
  RCC_OscInitStruct.PLL.PLLRGE = RCC_PLL1VCIRANGE_2;
  RCC_OscInitStruct.PLL.PLLVCOSEL = RCC_PLL1VCOWIDE;
  RCC_OscInitStruct.PLL.PLLFRACN = 0;
  if (HAL_RCC_OscConfig(&RCC_OscInitStruct) != HAL_OK)
  {
    Error_Handler();
  }

  /** Initializes the CPU, AHB and APB buses clocks
  */
  RCC_ClkInitStruct.ClockType = RCC_CLOCKTYPE_HCLK|RCC_CLOCKTYPE_SYSCLK
                              |RCC_CLOCKTYPE_PCLK1|RCC_CLOCKTYPE_PCLK2
                              |RCC_CLOCKTYPE_D3PCLK1|RCC_CLOCKTYPE_D1PCLK1;
  RCC_ClkInitStruct.SYSCLKSource = RCC_SYSCLKSOURCE_PLLCLK;
  RCC_ClkInitStruct.SYSCLKDivider = RCC_SYSCLK_DIV1;
  RCC_ClkInitStruct.AHBCLKDivider = RCC_HCLK_DIV2;
  RCC_ClkInitStruct.APB3CLKDivider = RCC_APB3_DIV2;
  RCC_ClkInitStruct.APB1CLKDivider = RCC_APB1_DIV2;
  RCC_ClkInitStruct.APB2CLKDivider = RCC_APB2_DIV2;
  RCC_ClkInitStruct.APB4CLKDivider = RCC_APB4_DIV2;

  if (HAL_RCC_ClockConfig(&RCC_ClkInitStruct, FLASH_LATENCY_4) != HAL_OK)
  {
    Error_Handler();
  }

  /** Enables the Clock Security System
  */
  HAL_RCC_EnableCSS();
}

void PeriphCommonClock_Config(void)
{
  RCC_PeriphCLKInitTypeDef PeriphClkInitStruct = {0};

  /** Initializes the peripherals clock
  */
  PeriphClkInitStruct.PeriphClockSelection = RCC_PERIPHCLK_ADC|RCC_PERIPHCLK_SAI1
                              |RCC_PERIPHCLK_SPI2|RCC_PERIPHCLK_SPI1;
  PeriphClkInitStruct.PLL2.PLL2M = 5;
  PeriphClkInitStruct.PLL2.PLL2N = 98;
  PeriphClkInitStruct.PLL2.PLL2P = 10;
  PeriphClkInitStruct.PLL2.PLL2Q = 4;
  PeriphClkInitStruct.PLL2.PLL2R = 2;
  PeriphClkInitStruct.PLL2.PLL2RGE = RCC_PLL2VCIRANGE_2;
  PeriphClkInitStruct.PLL2.PLL2VCOSEL = RCC_PLL2VCOWIDE;
  PeriphClkInitStruct.PLL2.PLL2FRACN = 2491;
  PeriphClkInitStruct.Sai1ClockSelection = RCC_SAI1CLKSOURCE_PLL2;
  PeriphClkInitStruct.Spi123ClockSelection = RCC_SPI123CLKSOURCE_PLL2;
  PeriphClkInitStruct.AdcClockSelection = RCC_ADCCLKSOURCE_PLL2;
  if (HAL_RCCEx_PeriphCLKConfig(&PeriphClkInitStruct) != HAL_OK)
  {
    Error_Handler();
  }
}

/* USER CODE BEGIN 4 */

void HAL_TIM_PWM_PulseFinishedCallback(TIM_HandleTypeDef *htim)
{
  BSP_LED_TIM_PWM_PulseFinishedCallback((void *)htim->Instance);
}

void HAL_I2S_TxCpltCallback(I2S_HandleTypeDef *hi2s)
{
  if (hi2s->Instance == SPI1)
  {
    BSP_AUDIO_OUT_TransferCompleteCallback();
  }
}

void HAL_I2S_ErrorCallback(I2S_HandleTypeDef *hi2s)
{
  if (hi2s->Instance == SPI1)
  {
    BSP_AUDIO_OUT_ErrorCallback(hi2s->ErrorCode);
  }
}

void HAL_I2S_TxHalfCpltCallback(I2S_HandleTypeDef *hi2s)
{
  if (hi2s->Instance == SPI1)
  {
    BSP_AUDIO_OUT_HalfTransferCallback();
  }
}

void HAL_SAI_RxHalfCpltCallback(SAI_HandleTypeDef *hsai)
{
  if (hsai->Instance == SAI1_Block_A)
  {
    BSP_AUDIO_IN_HalfTransferCallback();
  }
}

void HAL_SAI_RxCpltCallback(SAI_HandleTypeDef *hsai)
{
  if (hsai->Instance == SAI1_Block_A)
  {
    BSP_AUDIO_IN_TransferCompleteCallback();
  }
}

void HAL_SAI_ErrorCallback(SAI_HandleTypeDef *hsai)
{
  if (hsai->Instance == SAI1_Block_A)
  {
    BSP_AUDIO_IN_ErrorCallback(hsai->ErrorCode);
  }
}

/* USER CODE END 4 */

 /* MPU Configuration */

void MPU_Config(void)
{
  MPU_Region_InitTypeDef MPU_InitStruct = {0};

  /* Disables the MPU */
  HAL_MPU_Disable();

  /** Initializes and configures the Region and the memory to be protected
  */
  MPU_InitStruct.Enable = MPU_REGION_ENABLE;
  MPU_InitStruct.Number = MPU_REGION_NUMBER0;
  MPU_InitStruct.BaseAddress = 0x0;
  MPU_InitStruct.Size = MPU_REGION_SIZE_4GB;
  MPU_InitStruct.SubRegionDisable = 0x87;
  MPU_InitStruct.TypeExtField = MPU_TEX_LEVEL0;
  MPU_InitStruct.AccessPermission = MPU_REGION_NO_ACCESS;
  MPU_InitStruct.DisableExec = MPU_INSTRUCTION_ACCESS_DISABLE;
  MPU_InitStruct.IsShareable = MPU_ACCESS_SHAREABLE;
  MPU_InitStruct.IsCacheable = MPU_ACCESS_NOT_CACHEABLE;
  MPU_InitStruct.IsBufferable = MPU_ACCESS_NOT_BUFFERABLE;

  HAL_MPU_ConfigRegion(&MPU_InitStruct);

  /** Initializes and configures the Region and the memory to be protected
  */
  MPU_InitStruct.Number = MPU_REGION_NUMBER1;
  MPU_InitStruct.BaseAddress = 0x90000000;
  MPU_InitStruct.Size = MPU_REGION_SIZE_16MB;
  MPU_InitStruct.SubRegionDisable = 0x00;
  /* TouchGFX assets are immutable at runtime: cache repeated reads while
     preventing accidental writes and instruction fetches from external NOR. */
  MPU_InitStruct.AccessPermission = MPU_REGION_PRIV_RO_URO;
  MPU_InitStruct.IsShareable = MPU_ACCESS_NOT_SHAREABLE;
  MPU_InitStruct.IsCacheable = MPU_ACCESS_CACHEABLE;
  MPU_InitStruct.IsBufferable = MPU_ACCESS_NOT_BUFFERABLE;

  HAL_MPU_ConfigRegion(&MPU_InitStruct);

  /** AXI SRAM framebuffer: LTDC and DMA2D access this region directly, so it
      must remain non-cacheable even while the Cortex-M7 D-Cache is enabled. */
  MPU_InitStruct.Number = MPU_REGION_NUMBER2;
  MPU_InitStruct.BaseAddress = 0x24000000;
  MPU_InitStruct.Size = MPU_REGION_SIZE_512KB;
  MPU_InitStruct.SubRegionDisable = 0x00;
  MPU_InitStruct.TypeExtField = MPU_TEX_LEVEL0;
  MPU_InitStruct.AccessPermission = MPU_REGION_FULL_ACCESS;
  MPU_InitStruct.DisableExec = MPU_INSTRUCTION_ACCESS_DISABLE;
  MPU_InitStruct.IsShareable = MPU_ACCESS_NOT_SHAREABLE;
  MPU_InitStruct.IsCacheable = MPU_ACCESS_NOT_CACHEABLE;
  MPU_InitStruct.IsBufferable = MPU_ACCESS_NOT_BUFFERABLE;

  HAL_MPU_ConfigRegion(&MPU_InitStruct);
  /* Enables the MPU */
  HAL_MPU_Enable(MPU_PRIVILEGED_DEFAULT);

}

void HAL_TIM_PeriodElapsedCallback(TIM_HandleTypeDef *htim)
{
  if (htim->Instance == TIM6)
  {
    HAL_IncTick();
  }
  /* USER CODE BEGIN Callback 1 */
  if (htim->Instance == TIM6)
  {
    BSP_LCD_BacklightTick1ms();
  }
  /* USER CODE END Callback 1 */
}

void Error_Handler(void)
{
  __disable_irq();
  while (1)
  {
  }
}

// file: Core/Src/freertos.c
/* USER CODE BEGIN Header */
/**
  ******************************************************************************
  * File Name          : freertos.c
  * Description        : Code for freertos applications
  ******************************************************************************
  * @attention
  *
  * Copyright (c) 2026 STMicroelectronics.
  * All rights reserved.
  *
  * This software is licensed under terms that can be found in the LICENSE file
  * in the root directory of this software component.
  * If no LICENSE file comes with this software, it is provided AS-IS.
  *
  ******************************************************************************
  */
/* USER CODE END Header */

#include "FreeRTOS.h"
#include "task.h"
#include "main.h"
#include "FreeRTOS.h"
#include "cmsis_os2.h"

/* USER CODE BEGIN Includes */
#include "app_tasks.h"
#include "app_reminders.h"
#include "app.h"

/* USER CODE END Includes */

/* Definitions for SystemTask */
osThreadId_t SystemTaskHandle;
const osThreadAttr_t SystemTask_attributes = {
  .name = "SystemTask",
  .stack_size = 1024 * 4,
  .priority = (osPriority_t) osPriorityAboveNormal,
};
/* Definitions for TouchGFXTask */
osThreadId_t TouchGFXTaskHandle;
const osThreadAttr_t TouchGFXTask_attributes = {
  .name = "TouchGFXTask",
  .stack_size = 4096 * 4,
  .priority = (osPriority_t) osPriorityNormal,
};
/* Definitions for AudioInputTask */
osThreadId_t AudioInputTaskHandle;
const osThreadAttr_t AudioInputTask_attributes = {
  .name = "AudioInputTask",
  .stack_size = 2048 * 4,
  .priority = (osPriority_t) osPriorityHigh,
};
/* Definitions for WiFiTask */
osThreadId_t WiFiTaskHandle;
const osThreadAttr_t WiFiTask_attributes = {
  .name = "WiFiTask",
  .stack_size = 2048 * 4,
  .priority = (osPriority_t) osPriorityAboveNormal,
};
/* Definitions for SensorTask */
osThreadId_t SensorTaskHandle;
const osThreadAttr_t SensorTask_attributes = {
  .name = "SensorTask",
  .stack_size = 1024 * 4,
  .priority = (osPriority_t) osPriorityNormal,
};
/* Definitions for PowerTask */
osThreadId_t PowerTaskHandle;
const osThreadAttr_t PowerTask_attributes = {
  .name = "PowerTask",
  .stack_size = 512 * 4,
  .priority = (osPriority_t) osPriorityLow,
};
/* Definitions for LEDTask */
osThreadId_t LEDTaskHandle;
const osThreadAttr_t LEDTask_attributes = {
  .name = "LEDTask",
  .stack_size = 512 * 4,
  .priority = (osPriority_t) osPriorityAboveNormal,
};
/* Definitions for LoggingTask */
osThreadId_t LoggingTaskHandle;
const osThreadAttr_t LoggingTask_attributes = {
  .name = "LoggingTask",
  .stack_size = 1024 * 4,
  .priority = (osPriority_t) osPriorityLow,
};
/* Definitions for AudioOutputTask */
osThreadId_t AudioOutputTaskHandle;
const osThreadAttr_t AudioOutputTask_attributes = {
  .name = "AudioOutputTask",
  .stack_size = 2048 * 4,
  .priority = (osPriority_t) osPriorityHigh,
};
/* Definitions for WiFiReadySem */
osSemaphoreId_t WiFiReadySemHandle;
const osSemaphoreAttr_t WiFiReadySem_attributes = {
  .name = "WiFiReadySem"
};

void System_Task(void *argument);
extern void TouchGFX_Task(void *argument);
void AudioInput_Task(void *argument);
void WiFi_Task(void *argument);
void Sensor_Task(void *argument);
void Power_Task(void *argument);
void LED_Task(void *argument);
void Logging_Task(void *argument);
void AudioOutput_Task(void *argument);

void MX_FREERTOS_Init(void); /* (MISRA C 2004 rule 8.1) */

/* Hook prototypes */
void vApplicationStackOverflowHook(xTaskHandle xTask, char *pcTaskName);

/* USER CODE BEGIN 4 */
void vApplicationStackOverflowHook(xTaskHandle xTask, char *pcTaskName)
{
   /* Run time stack overflow checking is performed if
   configCHECK_FOR_STACK_OVERFLOW is defined to 1 or 2. This hook function is
   called if a stack overflow is detected. */
}
/* USER CODE END 4 */

void MX_FREERTOS_Init(void) {
/* USER CODE BEGIN Init */
  APP_TasksInit();
  APP_RemindersInit();

  /* USER CODE END Init */

  /* Create the semaphores(s) */
  /* creation of WiFiReadySem */
  WiFiReadySemHandle = osSemaphoreNew(1, 0, &WiFiReadySem_attributes);

  /* Create the thread(s) */
  /* creation of SystemTask */
  SystemTaskHandle = osThreadNew(System_Task, NULL, &SystemTask_attributes);

  /* creation of TouchGFXTask */
  TouchGFXTaskHandle = osThreadNew(TouchGFX_Task, NULL, &TouchGFXTask_attributes);

  /* creation of AudioInputTask */
  AudioInputTaskHandle = osThreadNew(AudioInput_Task, NULL, &AudioInputTask_attributes);

  /* creation of WiFiTask */
  WiFiTaskHandle = osThreadNew(WiFi_Task, NULL, &WiFiTask_attributes);

  /* creation of SensorTask */
  SensorTaskHandle = osThreadNew(Sensor_Task, NULL, &SensorTask_attributes);

  /* creation of PowerTask */
  PowerTaskHandle = osThreadNew(Power_Task, NULL, &PowerTask_attributes);

  /* creation of LEDTask */
  LEDTaskHandle = osThreadNew(LED_Task, NULL, &LEDTask_attributes);

  /* creation of LoggingTask */
  LoggingTaskHandle = osThreadNew(Logging_Task, NULL, &LoggingTask_attributes);

  /* creation of AudioOutputTask */
  AudioOutputTaskHandle = osThreadNew(AudioOutput_Task, NULL, &AudioOutputTask_attributes);

}

void System_Task(void *argument)
{
  /* USER CODE BEGIN System_Task */
  APP_SystemTask();
  /* USER CODE END System_Task */
}

void AudioInput_Task(void *argument)
{
  /* USER CODE BEGIN AudioInput_Task */
  APP_AudioInputTask();
  /* USER CODE END AudioInput_Task */
}

void WiFi_Task(void *argument)
{
  /* USER CODE BEGIN WiFi_Task */
  APP_WiFiTask();
  /* USER CODE END WiFi_Task */
}

void Sensor_Task(void *argument)
{
  /* USER CODE BEGIN Sensor_Task */
  APP_SensorTask();
  /* USER CODE END Sensor_Task */
}

void Power_Task(void *argument)
{
  /* USER CODE BEGIN Power_Task */
  APP_PowerTask();
  /* USER CODE END Power_Task */
}

void LED_Task(void *argument)
{
  /* USER CODE BEGIN LED_Task */
  APP_LEDTask();
  /* USER CODE END LED_Task */
}

void Logging_Task(void *argument)
{
  /* USER CODE BEGIN Logging_Task */
  /* No logging service yet: park the task instead of waking every tick. */
  for(;;)
  {
    osDelay(osWaitForever);
  }
  /* USER CODE END Logging_Task */
}

void AudioOutput_Task(void *argument)
{
  /* USER CODE BEGIN AudioOutput_Task */
  APP_AudioOutputTask();
  /* USER CODE END AudioOutput_Task */
}
